AUTOSAR XML (schema 00049)
package /Application/DltConfig
  dlt log channel to process mapping DltLogChannelToProcessMapping_SOA_Wiper_TO_SOA_Wiper: dlt-log-channel=SOA_Wiper, process=SOA_Wiper
package /Application/Executable
  executable SOA_Wiper: category=APPLICATION_LEVEL, logging-behavior=USES-LOGGING, reporting-behavior=REPORTS-EXECUTION-STATE, version=1.0.0
    root sw component prototype AA: application-type=SOA_Wiper
package /Application/Manifest
  5 x service instance to port prototype mapping, all with process=SOA_Wiper:
    SOA_Wiper_AA_PPort_SOA_VehicleInfo: port-prototype=AA.PPort_SOA_VehicleInfo, service-instance=Provider_SoaVehicleInfo
    SOA_Wiper_AA_PPort_SOA_Wiper: port-prototype=AA.PPort_SOA_Wiper, service-instance=Provider_SoaWiper
    SOA_Wiper_AA_RPort_Zone1Mfsw: port-prototype=AA.RPort_Zone1Mfsw, service-instance=Consumer_SoaWiper_MFSW
    SOA_Wiper_AA_RPort_Zone1VehicleInfo: port-prototype=AA.RPort_Zone1VehicleInfo, service-instance=Consumer_SoaWiper_VehicleInfo
    SOA_Wiper_AA_RPort_Zone4Wiper: port-prototype=AA.RPort_Zone4Wiper, service-instance=Consumer_Zone4Wiper
package /Application/Package/SOA_Wiper/SoftwareCluster_1_0_0
  software cluster SOA_Wiper_SoftwareCluster: category=APPLICATION_LAYER, contained-ar-element=SOA_Wiper, contained-package-element=[SOA_Wiper_AA_PPort_SOA_Wiper, SOA_Wiper_AA_RPort_Zone4Wiper], contained-process=SOA_Wiper, vendor-id=79, vendor-signature=ParaCertificate, version=1.0.0
package /Application/Package/SOA_Wiper/SoftwareCluster_1_0_1
  software cluster SOA_Wiper_SoftwareCluster: category=APPLICATION_LAYER, contained-ar-element=SOA_Wiper, contained-package-element=[SOA_Wiper_AA_PPort_SOA_Wiper, SOA_Wiper_AA_RPort_Zone4Wiper], contained-process=SOA_Wiper, vendor-id=79, vendor-signature=ParaCertificate, version=1.0.1
package /Application/Package/SOA_Wiper/SoftwareCluster_1_0_2
  software cluster SOA_Wiper_SoftwareCluster: category=APPLICATION_LAYER, contained-ar-element=SOA_Wiper, contained-package-element=[SOA_Wiper_AA_PPort_SOA_Wiper, SOA_Wiper_AA_RPort_Zone4Wiper], contained-process=SOA_Wiper, vendor-id=79, vendor-signature=ParaCertificate, version=1.0.2
package /Application/Package/SOA_Wiper/SoftwarePackage
  software package SOA_Wiper_InstallSoftwarePackage_1_0_0: action-type=INSTALL, compressed-software-package-size=0, maximum-supported-ucm-version=1.0.0, minimum-supported-ucm-version=1.0.0, packager-id=79, packager-signature=ParaCertificate, post-verification-reboot=false, pre-activate=SC.Off, pre-activation-reboot=false, software-cluster=SoftwareCluster_1_0_0/SOA_Wiper_SoftwareCluster, uncompressed-software-cluster-size=0, verify=SC.Verify
  software package SOA_Wiper_RemoveSoftwarePackage_1_0_2: action-type=REMOVE, compressed-software-package-size=0, maximum-supported-ucm-version=1.0.0, minimum-supported-ucm-version=1.0.0, packager-id=79, packager-signature=ParaCertificate, post-verification-reboot=false, pre-activate=SC.Off, pre-activation-reboot=false, software-cluster=SoftwareCluster_1_0_2/SOA_Wiper_SoftwareCluster, uncompressed-software-cluster-size=0, verify=SC.Verify
  software package SOA_Wiper_UpdateSoftwarePackage_1_0_1: action-type=UPDATE, compressed-software-package-size=0, maximum-supported-ucm-version=1.0.0, minimum-supported-ucm-version=1.0.0, packager-id=79, packager-signature=ParaCertificate, post-verification-reboot=false, pre-activate=SC.Off, pre-activation-reboot=false, software-cluster=SoftwareCluster_1_0_1/SOA_Wiper_SoftwareCluster, uncompressed-software-cluster-size=0, verify=SC.Verify
package /Application/Package/SOA_Wiper/VehiclePackage
  vehicle package SOA_Wiper_InstallVehiclePackage_1_0_0: vehicle-driver-notification{approval-required=true, notification-state=PROCESS}, packager-signature=ParaCertificate
    rollout-qualifications:
      vehicle rollout step RolloutQualification0
        ucm-processings:
          ucm step UcmProcessing0: ucm=SOA_Wiper_InstallVehiclePackage_1_0_0/EEVP_UCM
            software package step SoftwarePackageStep0: process=SOA_Wiper_InstallSoftwarePackage_1_0_0, transfers=software-package-storing={storing=UCM, transfer=SOA_Wiper_InstallSoftwarePackage_1_0_0}
    ucm description EEVP_UCM: identifier=EEVP_UCM
  vehicle package SOA_Wiper_RemoveVehiclePackage_1_0_2: vehicle-driver-notification{approval-required=true, notification-state=PROCESS}, packager-signature=ParaCertificate
    rollout-qualifications:
      vehicle rollout step RolloutQualification0
        ucm-processings:
          ucm step UcmProcessing0: ucm=SOA_Wiper_RemoveVehiclePackage_1_0_2/EEVP_UCM
            software package step SoftwarePackageStep0: process=SOA_Wiper_RemoveSoftwarePackage_1_0_2, transfers=software-package-storing={storing=UCM, transfer=SOA_Wiper_RemoveSoftwarePackage_1_0_2}
    ucm description EEVP_UCM: identifier=EEVP_UCM
  vehicle package SOA_Wiper_UpdateVehiclePackage_1_0_1: vehicle-driver-notification{approval-required=true, notification-state=PROCESS}, packager-signature=ParaCertificate
    rollout-qualifications:
      vehicle rollout step RolloutQualification0
        ucm-processings:
          ucm step UcmProcessing0: ucm=SOA_Wiper_UpdateVehiclePackage_1_0_1/EEVP_UCM
            software package step SoftwarePackageStep0: process=SOA_Wiper_UpdateSoftwarePackage_1_0_1, transfers=software-package-storing={storing=UCM, transfer=SOA_Wiper_UpdateSoftwarePackage_1_0_1}
    ucm description EEVP_UCM: identifier=EEVP_UCM
package /Application/Process
  process SOA_Wiper: executable=SOA_Wiper, state-dependent-startup-config{function-group-state=[SC.On, SC.Verify], resource-group=DefaultResourceGroup, startup-config=SOA}
    process state machine SOA_Wiper: type=ProcessState
package /Application/SwComponent
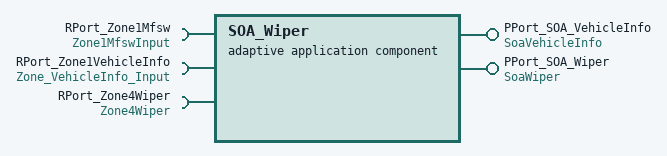
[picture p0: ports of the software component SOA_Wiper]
  adaptive application sw component type SOA_Wiper
    provide port PPort_SOA_VehicleInfo: provided-interface=SoaVehicleInfo
    provide port PPort_SOA_Wiper: provided-interface=SoaWiper
    require port RPort_Zone1Mfsw: required-interface=Zone1MfswInput
    require port RPort_Zone1VehicleInfo: required-interface=Zone_VehicleInfo_Input
    require port RPort_Zone4Wiper: required-interface=Zone4Wiper
